# M4G8 register map
File version: 0.1
Registers are 32-bit, read-write, reset 0x0 unless marked. A register's access mark holds for its fields unless they carry their own. Offsets are from the block's base; [hi:lo] are bit positions; {n}, {i} and the like mark numbered series.

## PR — Port R
Base 0x400E0E00
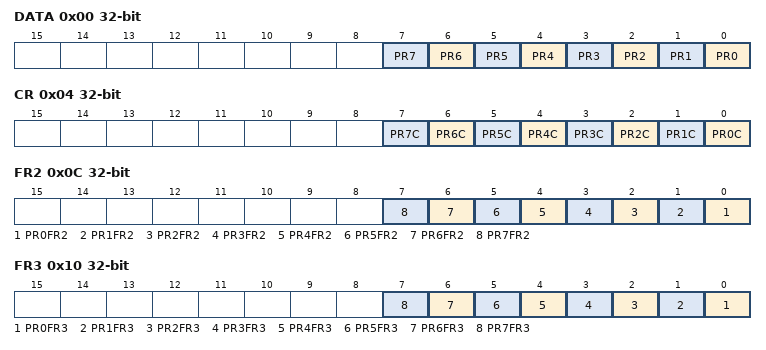
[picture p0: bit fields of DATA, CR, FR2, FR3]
0x00 DATA — Port R Data Register
  [n] PR{n} (n=0..7)
0x04 CR — Port R Output Control Register
  [n] PR{n}C (n=0..7)
0x0C FR2 — Port R Function Register 2
  [n] PR{n}FR2 (n=0..7)
0x10 FR3 — Port R Function Register 3
  [n] PR{n}FR3 (n=0..7)
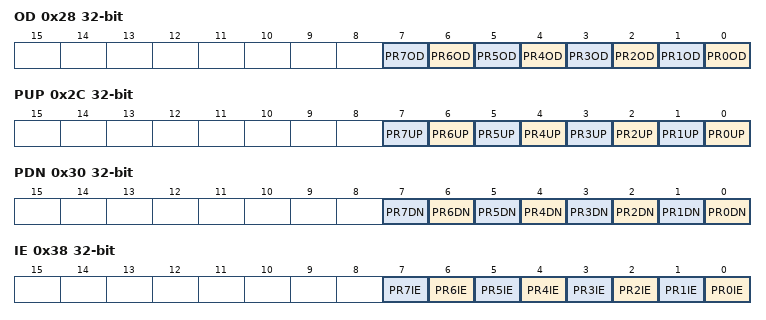
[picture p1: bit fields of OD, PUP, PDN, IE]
0x28 OD — Port R Open Drain Control Register
  [n] PR{n}OD (n=0..7)
0x2C PUP — Port R Pull-up Control Register
  [n] PR{n}UP (n=0..7)
0x30 PDN — Port R Pull-down Control Register
  [n] PR{n}DN (n=0..7)
0x38 IE — Port R Input Control Register
  [n] PR{n}IE (n=0..7)

## PT — Port T
Base 0x400E0F00
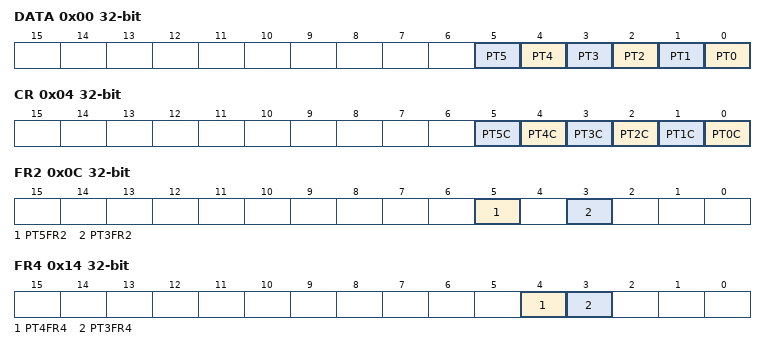
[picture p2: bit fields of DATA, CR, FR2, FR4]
0x00 DATA — Port T Data Register
  [n] PT{n} (n=0..5)
0x04 CR — Port T Output Control Register
  [n] PT{n}C (n=0..5)
0x08 FR1 — Port T Function Register 1
  [3] PT3FR1
0x0C FR2 — Port T Function Register 2
  [5] PT5FR2, [3] PT3FR2
0x10 FR3 — Port T Function Register 3
  [3] PT3FR3
0x14 FR4 — Port T Function Register 4
  [4] PT4FR4, [3] PT3FR4
0x1C FR6 — Port T Function Register 6
  [3] PT3FR6
0x20 FR7 — Port T Function Register 7
  [2] PT2FR7
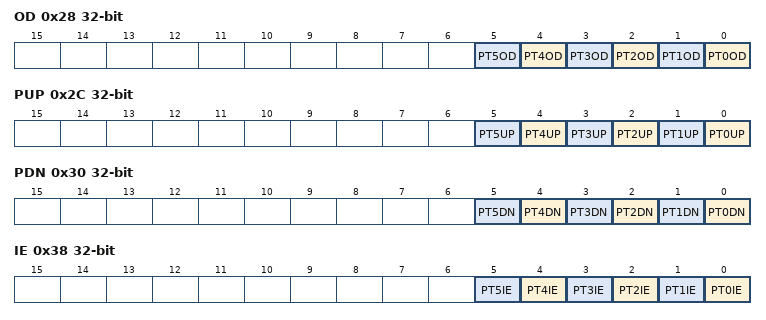
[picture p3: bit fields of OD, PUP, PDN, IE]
0x28 OD — Port T Open Drain Control Register
  [n] PT{n}OD (n=0..5)
0x2C PUP — Port T Pull-up Control Register
  [n] PT{n}UP (n=0..5)
0x30 PDN — Port T Pull-down Control Register
  [n] PT{n}DN (n=0..5)
0x38 IE — Port T Input Control Register
  [n] PT{n}IE (n=0..5)

## PV — Port V
Base 0x400E1100
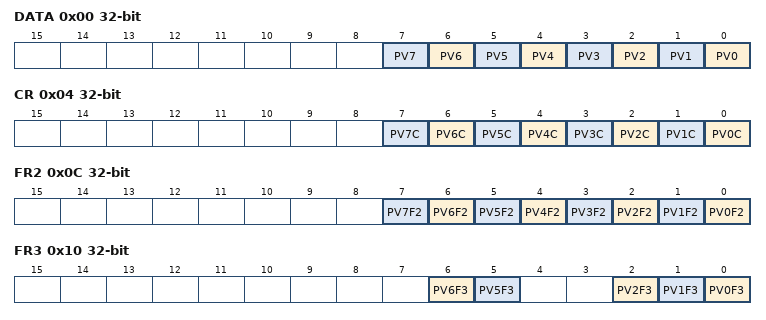
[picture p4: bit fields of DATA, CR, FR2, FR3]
0x00 DATA — Port V Data Register
  [n] PV{n} (n=0..7)
0x04 CR — Port V OutPut Control Register
  [n] PV{n}C (n=0..7)
0x0C FR2 — Port V Function Register 2
  [n] PV{n}F2 (n=0..7)
0x10 FR3 — Port V Function Register 3
  [6] PV6F3, [5] PV5F3, [2] PV2F3, [1] PV1F3, [0] PV0F3
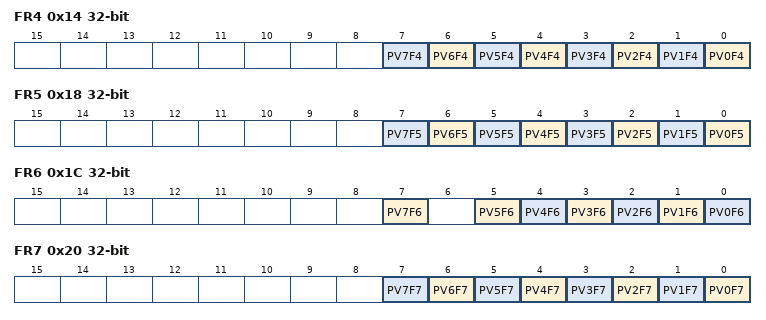
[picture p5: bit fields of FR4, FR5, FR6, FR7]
0x14 FR4 — Port V Function Register 4
  [n] PV{n}F4 (n=0..7)
0x18 FR5 — Port V Function Register 5
  [n] PV{n}F5 (n=0..7)
0x1C FR6 — Port V Function Register 6
  [7] PV7F6, [n] PV{n}F6 (n=0..5)
0x20 FR7 — Port V Function Register 7
  [n] PV{n}F7 (n=0..7)
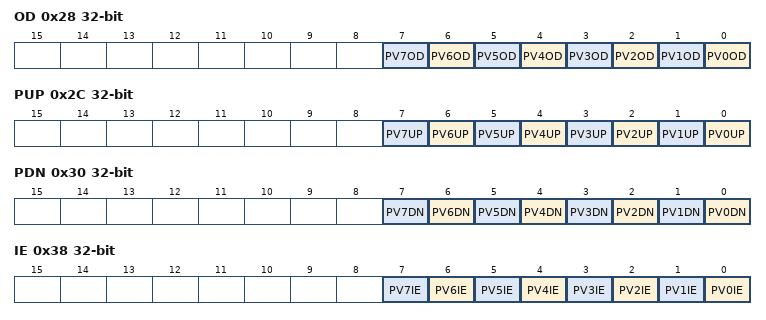
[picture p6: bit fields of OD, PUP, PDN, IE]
0x28 OD — Port V Open Drain Control Register
  [n] PV{n}OD (n=0..7)
0x2C PUP — Port V Pull-up Control Register
  [n] PV{n}UP (n=0..7)
0x30 PDN — Port V Pull-down Control Register
  [n] PV{n}DN (n=0..7)
0x38 IE — Port V InPut Control Register
  [n] PV{n}IE (n=0..7)

## PY — Port Y
Base 0x400E1300
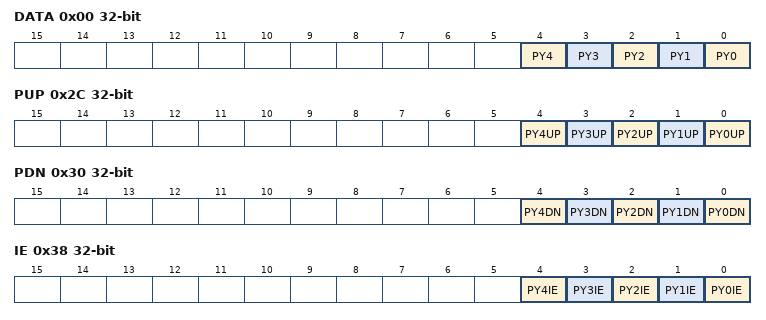
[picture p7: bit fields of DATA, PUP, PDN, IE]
0x00 DATA — Port Y Data Register
  [n] PY{n} (n=0..4)
0x04 CR — Port Y OutPut Control Register
  [4] PY4C
0x08 FR1 — Port Y Function Register 1
  [4] PY4F1
0x14 FR4 — Port Y Function Register 4
  [4] PY4F4
0x28 OD — Port Y Open Drain Control Register
  [4] PY4OD
0x2C PUP — Port Y Pull-up Control Register
  [n] PY{n}UP (n=0..4)
0x30 PDN — Port Y Pull-down Control Register
  [n] PY{n}DN (n=0..4)
0x38 IE — Port Y InPut Control Register
  [n] PY{n}IE (n=0..4)

## TRMOSC — Internal High-speed Oscillation Adjustment
Base 0x400E3100
0x00 PRO — Protection Register
  [7:0] PROTECT
0x04 EN — Enable Register
  [0] TRIMEN
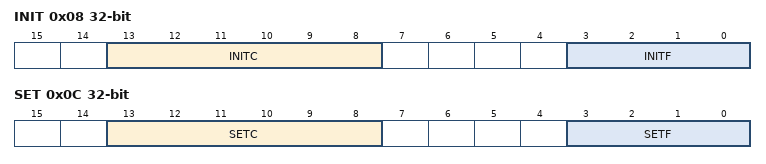
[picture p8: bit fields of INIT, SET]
0x08 INIT ro (reset mask 0xFFFFC0F0) — Initial Trimming Level Monitor Register
  [13:8] INITC, [3:0] INITF
0x0C SET — Trimming Level Setting Register
  [13:8] SETC, [3:0] SETF

## OFD — Oscillation Frequency Detector (OFD)
Base 0x400E4000
0x00 CR1 reset 0x6 — OFD Control Register 1
  [7:0] OFDWEN
0x04 CR2 — OFD Control Register 2
  [7:0] OFDEN
0x08 MN0 — OFD Lower Detection Frequency Setting Register0
  [11:0] OFDMN0
0x0C MN1 — OFD Lower Detection Frequency Setting Register1
  [11:0] OFDMN1
0x10 MX0 — OFD Higher Detection Frequency Setting Register0
  [11:0] OFDMX0
0x14 MX1 — OFD Higher Detection Frequency Setting Register1
  [11:0] OFDMX1
0x18 RST reset 0x1 — OFD Reset Enable Control Register
  [0] OFDRSTEN
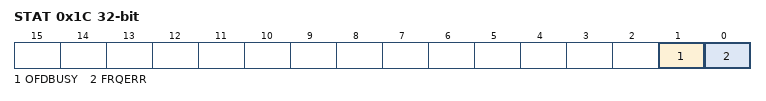
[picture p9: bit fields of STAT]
0x1C STAT ro — OFD Status Register
  [1] OFDBUSY, [0] FRQERR
0x20 MON reset 0x1 — OFD External high frequency oscillaion clock monitor register
  [0] OFDMON
